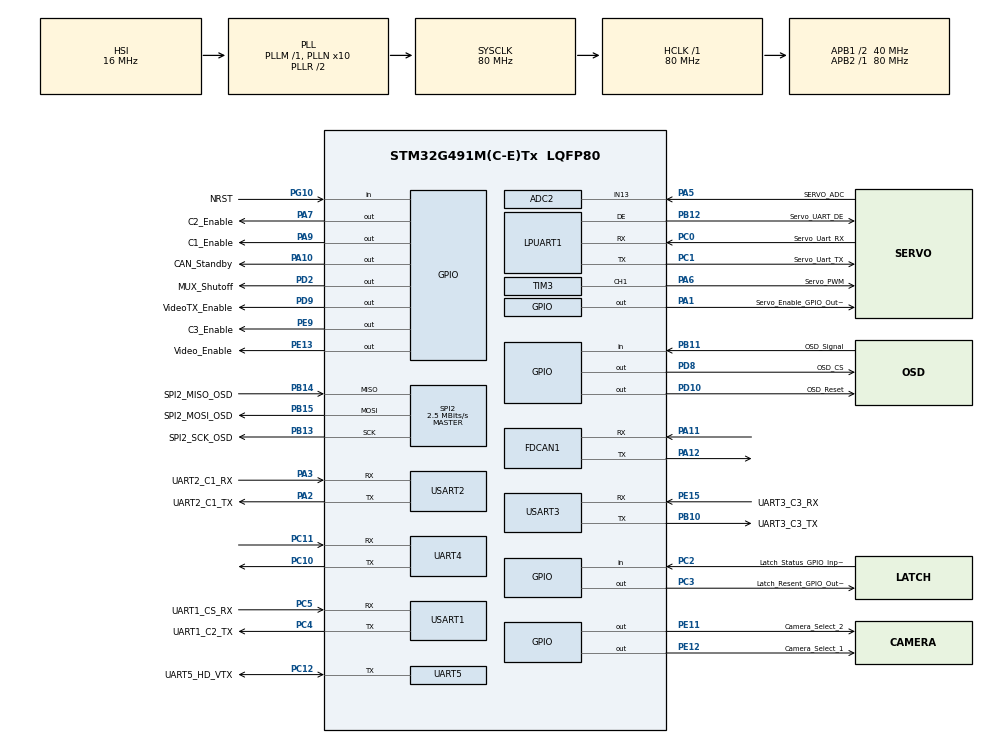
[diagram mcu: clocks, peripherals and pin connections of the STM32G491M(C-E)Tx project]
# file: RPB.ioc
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ADC2.Channel-0\#ChannelRegularConversion=ADC_CHANNEL_13
ADC2.NbrOfConversionFlag=1
ADC2.OffsetNumber-0\#ChannelRegularConversion=ADC_OFFSET_NONE
ADC2.Rank-0\#ChannelRegularConversion=1
ADC2.SamplingTime-0\#ChannelRegularConversion=ADC_SAMPLETIME_2CYCLES_5
FDCAN1.AutoRetransmission=ENABLE
FDCAN1.CalculateBaudRateNominal=1000000
FDCAN1.CalculateTimeBitNominal=1000
FDCAN1.CalculateTimeQuantumNominal=25.0
FDCAN1.DataSyncJumpWidth=7
FDCAN1.DataTimeSeg1=8
FDCAN1.DataTimeSeg2=7
FDCAN1.FrameFormat=FDCAN_FRAME_FD_BRS
FDCAN1.NominalPrescaler=1
FDCAN1.NominalSyncJumpWidth=6
FDCAN1.NominalTimeSeg1=33
FDCAN1.NominalTimeSeg2=6
FREERTOS.Tasks01=defaultTask,0,128,StartDefaultTask,Default,NULL,Dynamic,NULL,NULL
FREERTOS.configTOTAL_HEAP_SIZE=64000
FREERTOS.configUSE_NEWLIB_REENTRANT=1
Mcu.Family=STM32G4
Mcu.Name=STM32G491M(C-E)Tx
Mcu.Package=LQFP80
NVIC.FDCAN1_IT0_IRQn=true\:5\:0\:false\:false\:true\:true\:true\:true\:true
NVIC.PriorityGroup=NVIC_PRIORITYGROUP_4
NVIC.TIM4_IRQn=true\:15\:0\:false\:false\:true\:false\:false\:true\:true
NVIC.TimeBase=TIM4_IRQn
NVIC.TimeBaseIP=TIM4
NVIC.UART4_IRQn=true\:5\:0\:false\:false\:true\:true\:true\:true\:true
PA1.GPIO_Label=Servo_Enable_GPIO_Output
PA1.Signal=GPIO_Output
PA10.GPIO_Label=CAN_Standby
PA10.Signal=GPIO_Output
PA11.Mode=FDCAN_Activate
PA11.Signal=FDCAN1_RX
PA12.Mode=FDCAN_Activate
PA12.Signal=FDCAN1_TX
PA13.Mode=Trace_Asynchronous_SW
PA13.Signal=SYS_JTMS-SWDIO
PA14.Mode=Trace_Asynchronous_SW
PA14.Signal=SYS_JTCK-SWCLK
PA2.GPIO_Label=UART2_C1_TX
PA2.Mode=Asynchronous
PA2.Signal=USART2_TX
PA3.GPIO_Label=UART2_C1_RX
PA3.Mode=Asynchronous
PA3.Signal=USART2_RX
PA5.GPIO_Label=SERVO_ADC
PA5.Mode=IN13-Single-Ended
PA5.Signal=ADC2_IN13
PA6.GPIO_Label=Servo_PWM
PA6.Signal=S_TIM3_CH1
PA7.GPIO_Label=C2_Enable
PA7.Signal=GPIO_Output
PA9.GPIO_Label=C1_Enable
PA9.Signal=GPIO_Output
PB10.GPIO_Label=UART3_C3_TX
PB10.Mode=Asynchronous
PB10.Signal=USART3_TX
PB11.GPIO_Label=OSD_Signal
PB11.Signal=GPIO_Input
PB12.GPIO_Label=Servo_UART_DE
PB12.Mode=Hardware Flow Control (RS485)
PB12.Signal=LPUART1_DE
PB13.GPIO_Label=SPI2_SCK_OSD
PB13.Mode=Full_Duplex_Master
PB13.Signal=SPI2_SCK
PB14.GPIO_Label=SPI2_MISO_OSD
PB14.Mode=Full_Duplex_Master
PB14.Signal=SPI2_MISO
PB15.GPIO_Label=SPI2_MOSI_OSD
PB15.Mode=Full_Duplex_Master
PB15.Signal=SPI2_MOSI
PB3.Mode=Trace_Asynchronous_SW
PB3.Signal=SYS_JTDO-SWO
PC0.GPIO_Label=Servo_Uart_RX
PC0.Mode=Asynchronous
PC0.Signal=LPUART1_RX
PC1.GPIO_Label=Servo_Uart_TX
PC1.Mode=Asynchronous
PC1.Signal=LPUART1_TX
PC10.Mode=Asynchronous
PC10.Signal=UART4_TX
PC11.Mode=Asynchronous
PC11.Signal=UART4_RX
PC12.GPIO_Label=UART5_HD_VTX
PC12.Mode=Half_duplex(single_wire_mode)
PC12.Signal=UART5_TX
PC2.GPIO_Label=Latch_Status_GPIO_Input
PC2.Signal=GPIO_Input
PC3.GPIO_Label=Latch_Resent_GPIO_Output
PC3.Signal=GPIO_Output
PC4.GPIO_Label=UART1_C2_TX
PC4.Mode=Asynchronous
PC4.Signal=USART1_TX
PC5.GPIO_Label=UART1_CS_RX
PC5.Mode=Asynchronous
PC5.Signal=USART1_RX
PD10.GPIO_Label=OSD_Reset
PD10.Signal=GPIO_Output
PD2.GPIO_Label=MUX_Shutoff
PD2.Signal=GPIO_Output
PD8.GPIO_Label=OSD_CS
PD8.Signal=GPIO_Output
PD9.GPIO_Label=VideoTX_Enable
PD9.Signal=GPIO_Output
PE11.GPIO_Label=Camera_Select_2
PE11.Signal=GPIO_Output
PE12.GPIO_Label=Camera_Select_1
PE12.Signal=GPIO_Output
PE13.GPIO_Label=Video_Enable
PE13.Signal=GPIO_Output
PE15.GPIO_Label=UART3_C3_RX
PE15.Mode=Asynchronous
PE15.Signal=USART3_RX
PE9.GPIO_Label=C3_Enable
PE9.Signal=GPIO_Output
PG10-NRST.GPIO_Label=NRST
PG10-NRST.Signal=GPIO_Input
ProjectManager.HeapSize=0x200
ProjectManager.StackSize=0x400
ProjectManager.TargetToolchain=STM32CubeIDE
RCC.ADC12Freq_Value=80000000
RCC.ADC345Freq_Value=80000000
RCC.AHBFreq_Value=80000000
RCC.APB1CLKDivider=RCC_HCLK_DIV2
RCC.APB1Freq_Value=40000000
RCC.APB1TimFreq_Value=80000000
RCC.APB2Freq_Value=80000000
RCC.APB2TimFreq_Value=80000000
RCC.CortexFreq_Value=80000000
RCC.EXTERNAL_CLOCK_VALUE=12288000
RCC.HCLKFreq_Value=80000000
RCC.HSE_VALUE=8000000
RCC.HSI48_VALUE=48000000
RCC.HSI_VALUE=16000000
RCC.LSE_VALUE=32768
RCC.PLLN=10
RCC.SYSCLKFreq_VALUE=80000000
RCC.SYSCLKSource=RCC_SYSCLKSOURCE_PLLCLK
RCC.VCOOutputFreq_Value=160000000
SH.S_TIM3_CH1.0=TIM3_CH1,PWM Generation1 CH1
SPI2.BaudRatePrescaler=SPI_BAUDRATEPRESCALER_16
SPI2.CalculateBaudRate=2.5 MBits/s
SPI2.DataSize=SPI_DATASIZE_8BIT
SPI2.Direction=SPI_DIRECTION_2LINES
SPI2.Mode=SPI_MODE_MASTER
SPI2.VirtualType=VM_MASTER
TIM3.Channel-PWM\ Generation1\ CH1=TIM_CHANNEL_1
TIM3.Prescaler=16
UART5.BaudRate=9600
USART1.VirtualMode-Asynchronous=VM_ASYNC
USART2.VirtualMode-Asynchronous=VM_ASYNC
USART3.VirtualMode-Asynchronous=VM_ASYNC
VP_CRC_VS_CRC.Mode=CRC_Activate
VP_FREERTOS_VS_CMSIS_V1.Mode=CMSIS_V1
VP_SYS_VS_DBSignals.Mode=DisableDeadBatterySignals
VP_SYS_VS_tim4.Mode=TIM4
board=custom

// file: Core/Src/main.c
/* USER CODE BEGIN Header */
/**
  ******************************************************************************
  * @file           : main.c
  * @brief          : Main program body
  ******************************************************************************
  * @attention
  *
  * Copyright (c) 2025 STMicroelectronics.
  * All rights reserved.
  *
  * This software is licensed under terms that can be found in the LICENSE file
  * in the root directory of this software component.
  * If no LICENSE file comes with this software, it is provided AS-IS.
  *
  ******************************************************************************
  */
/* USER CODE END Header */
#include "main.h"
#include "cmsis_os.h"

/* USER CODE BEGIN Includes */
#include "RunInterface.hpp"
/* USER CODE END Includes */

ADC_HandleTypeDef hadc2;

CRC_HandleTypeDef hcrc;

FDCAN_HandleTypeDef hfdcan1;

UART_HandleTypeDef hlpuart1;

SPI_HandleTypeDef hspi2;

TIM_HandleTypeDef htim3;

osThreadId defaultTaskHandle;

void SystemClock_Config(void);
static void MX_GPIO_Init(void);
static void MX_FDCAN1_Init(void);
static void MX_UART4_Init(void);
static void MX_UART5_Init(void);
static void MX_USART1_UART_Init(void);
static void MX_USART2_UART_Init(void);
static void MX_USART3_UART_Init(void);
static void MX_LPUART1_UART_Init(void);
static void MX_ADC2_Init(void);
static void MX_SPI2_Init(void);
static void MX_TIM3_Init(void);
static void MX_CRC_Init(void);
void StartDefaultTask(void const * argument);

int main(void)
{

  /* MCU Configuration--------------------------------------------------------*/

  /* Reset of all peripherals, Initializes the Flash interface and the Systick. */
  HAL_Init();

  /* Configure the system clock */
  SystemClock_Config();

  /* Initialize all configured peripherals */
  MX_GPIO_Init();
  MX_FDCAN1_Init();
  MX_UART4_Init();
  MX_UART5_Init();
  MX_USART1_UART_Init();
  MX_USART2_UART_Init();
  MX_USART3_UART_Init();
  MX_LPUART1_UART_Init();
  MX_ADC2_Init();
  MX_SPI2_Init();
  MX_TIM3_Init();
  MX_CRC_Init();
  /* USER CODE BEGIN 2 */
  run_interface();
  /* USER CODE END 2 */

  /* Create the thread(s) */
  /* definition and creation of defaultTask */
  osThreadDef(defaultTask, StartDefaultTask, osPriorityNormal, 0, 128);
  defaultTaskHandle = osThreadCreate(osThread(defaultTask), NULL);

  /* Start scheduler */
  osKernelStart();

  /* We should never get here as control is now taken by the scheduler */

  /* Infinite loop */
  while (1)
  {

  }
}

void SystemClock_Config(void)
{
  RCC_OscInitTypeDef RCC_OscInitStruct = {0};
  RCC_ClkInitTypeDef RCC_ClkInitStruct = {0};

  /** Configure the main internal regulator output voltage
  */
  HAL_PWREx_ControlVoltageScaling(PWR_REGULATOR_VOLTAGE_SCALE1);

  /** Initializes the RCC Oscillators according to the specified parameters
  * in the RCC_OscInitTypeDef structure.
  */
  RCC_OscInitStruct.OscillatorType = RCC_OSCILLATORTYPE_HSI;
  RCC_OscInitStruct.HSIState = RCC_HSI_ON;
  RCC_OscInitStruct.HSICalibrationValue = RCC_HSICALIBRATION_DEFAULT;
  RCC_OscInitStruct.PLL.PLLState = RCC_PLL_ON;
  RCC_OscInitStruct.PLL.PLLSource = RCC_PLLSOURCE_HSI;
  RCC_OscInitStruct.PLL.PLLM = RCC_PLLM_DIV1;
  RCC_OscInitStruct.PLL.PLLN = 10;
  RCC_OscInitStruct.PLL.PLLP = RCC_PLLP_DIV2;
  RCC_OscInitStruct.PLL.PLLQ = RCC_PLLQ_DIV2;
  RCC_OscInitStruct.PLL.PLLR = RCC_PLLR_DIV2;
  if (HAL_RCC_OscConfig(&RCC_OscInitStruct) != HAL_OK)
  {
    Error_Handler();
  }

  /** Initializes the CPU, AHB and APB buses clocks
  */
  RCC_ClkInitStruct.ClockType = RCC_CLOCKTYPE_HCLK|RCC_CLOCKTYPE_SYSCLK
                              |RCC_CLOCKTYPE_PCLK1|RCC_CLOCKTYPE_PCLK2;
  RCC_ClkInitStruct.SYSCLKSource = RCC_SYSCLKSOURCE_PLLCLK;
  RCC_ClkInitStruct.AHBCLKDivider = RCC_SYSCLK_DIV1;
  RCC_ClkInitStruct.APB1CLKDivider = RCC_HCLK_DIV2;
  RCC_ClkInitStruct.APB2CLKDivider = RCC_HCLK_DIV1;

  if (HAL_RCC_ClockConfig(&RCC_ClkInitStruct, FLASH_LATENCY_2) != HAL_OK)
  {
    Error_Handler();
  }
}

static void MX_ADC2_Init(void)
{

  ADC_ChannelConfTypeDef sConfig = {0};

  /** Common config
  */
  hadc2.Instance = ADC2;
  hadc2.Init.ClockPrescaler = ADC_CLOCK_SYNC_PCLK_DIV2;
  hadc2.Init.Resolution = ADC_RESOLUTION_12B;
  hadc2.Init.DataAlign = ADC_DATAALIGN_RIGHT;
  hadc2.Init.GainCompensation = 0;
  hadc2.Init.ScanConvMode = ADC_SCAN_DISABLE;
  hadc2.Init.EOCSelection = ADC_EOC_SINGLE_CONV;
  hadc2.Init.LowPowerAutoWait = DISABLE;
  hadc2.Init.ContinuousConvMode = DISABLE;
  hadc2.Init.NbrOfConversion = 1;
  hadc2.Init.DiscontinuousConvMode = DISABLE;
  hadc2.Init.ExternalTrigConv = ADC_SOFTWARE_START;
  hadc2.Init.ExternalTrigConvEdge = ADC_EXTERNALTRIGCONVEDGE_NONE;
  hadc2.Init.DMAContinuousRequests = DISABLE;
  hadc2.Init.Overrun = ADC_OVR_DATA_PRESERVED;
  hadc2.Init.OversamplingMode = DISABLE;
  if (HAL_ADC_Init(&hadc2) != HAL_OK)
  {
    Error_Handler();
  }

  /** Configure Regular Channel
  */
  sConfig.Channel = ADC_CHANNEL_13;
  sConfig.Rank = ADC_REGULAR_RANK_1;
  sConfig.SamplingTime = ADC_SAMPLETIME_2CYCLES_5;
  sConfig.SingleDiff = ADC_SINGLE_ENDED;
  sConfig.OffsetNumber = ADC_OFFSET_NONE;
  sConfig.Offset = 0;
  if (HAL_ADC_ConfigChannel(&hadc2, &sConfig) != HAL_OK)
  {
    Error_Handler();
  }

}

static void MX_CRC_Init(void)
{

  hcrc.Instance = CRC;
  hcrc.Init.DefaultPolynomialUse = DEFAULT_POLYNOMIAL_ENABLE;
  hcrc.Init.DefaultInitValueUse = DEFAULT_INIT_VALUE_ENABLE;
  hcrc.Init.InputDataInversionMode = CRC_INPUTDATA_INVERSION_NONE;
  hcrc.Init.OutputDataInversionMode = CRC_OUTPUTDATA_INVERSION_DISABLE;
  hcrc.InputDataFormat = CRC_INPUTDATA_FORMAT_BYTES;
  if (HAL_CRC_Init(&hcrc) != HAL_OK)
  {
    Error_Handler();
  }

}

static void MX_FDCAN1_Init(void)
{

  hfdcan1.Instance = FDCAN1;
  hfdcan1.Init.ClockDivider = FDCAN_CLOCK_DIV1;
  hfdcan1.Init.FrameFormat = FDCAN_FRAME_FD_BRS;
  hfdcan1.Init.Mode = FDCAN_MODE_NORMAL;
  hfdcan1.Init.AutoRetransmission = ENABLE;
  hfdcan1.Init.TransmitPause = DISABLE;
  hfdcan1.Init.ProtocolException = DISABLE;
  hfdcan1.Init.NominalPrescaler = 1;
  hfdcan1.Init.NominalSyncJumpWidth = 6;
  hfdcan1.Init.NominalTimeSeg1 = 33;
  hfdcan1.Init.NominalTimeSeg2 = 6;
  hfdcan1.Init.DataPrescaler = 1;
  hfdcan1.Init.DataSyncJumpWidth = 7;
  hfdcan1.Init.DataTimeSeg1 = 8;
  hfdcan1.Init.DataTimeSeg2 = 7;
  hfdcan1.Init.StdFiltersNbr = 0;
  hfdcan1.Init.ExtFiltersNbr = 0;
  hfdcan1.Init.TxFifoQueueMode = FDCAN_TX_FIFO_OPERATION;
  if (HAL_FDCAN_Init(&hfdcan1) != HAL_OK)
  {
    Error_Handler();
  }

}

static void MX_LPUART1_UART_Init(void)
{

  hlpuart1.Instance = LPUART1;
  hlpuart1.Init.BaudRate = 209700;
  hlpuart1.Init.WordLength = UART_WORDLENGTH_8B;
  hlpuart1.Init.StopBits = UART_STOPBITS_1;
  hlpuart1.Init.Parity = UART_PARITY_NONE;
  hlpuart1.Init.Mode = UART_MODE_TX_RX;
  hlpuart1.Init.HwFlowCtl = UART_HWCONTROL_NONE;
  hlpuart1.Init.OneBitSampling = UART_ONE_BIT_SAMPLE_DISABLE;
  hlpuart1.Init.ClockPrescaler = UART_PRESCALER_DIV1;
  hlpuart1.AdvancedInit.AdvFeatureInit = UART_ADVFEATURE_NO_INIT;
  if (HAL_UART_Init(&hlpuart1) != HAL_OK)
  {
    Error_Handler();
  }
  if (HAL_UARTEx_SetTxFifoThreshold(&hlpuart1, UART_TXFIFO_THRESHOLD_1_8) != HAL_OK)
  {
    Error_Handler();
  }
  if (HAL_UARTEx_SetRxFifoThreshold(&hlpuart1, UART_RXFIFO_THRESHOLD_1_8) != HAL_OK)
  {
    Error_Handler();
  }
  if (HAL_UARTEx_DisableFifoMode(&hlpuart1) != HAL_OK)
  {
    Error_Handler();
  }
  if (HAL_RS485Ex_Init(&hlpuart1, UART_DE_POLARITY_HIGH, 0, 0) != HAL_OK)
  {
    Error_Handler();
  }

}

static void MX_UART4_Init(void)
{

  LL_USART_InitTypeDef USART_InitStruct = {0};

  LL_GPIO_InitTypeDef GPIO_InitStruct = {0};
  RCC_PeriphCLKInitTypeDef PeriphClkInit = {0};

  /** Initializes the peripherals clocks
  */
  PeriphClkInit.PeriphClockSelection = RCC_PERIPHCLK_UART4;
  PeriphClkInit.Uart4ClockSelection = RCC_UART4CLKSOURCE_PCLK1;
  if (HAL_RCCEx_PeriphCLKConfig(&PeriphClkInit) != HAL_OK)
  {
    Error_Handler();
  }

  /* Peripheral clock enable */
  LL_APB1_GRP1_EnableClock(LL_APB1_GRP1_PERIPH_UART4);

  LL_AHB2_GRP1_EnableClock(LL_AHB2_GRP1_PERIPH_GPIOC);
  /**UART4 GPIO Configuration
  PC10   ------> UART4_TX
  PC11   ------> UART4_RX
  */
  GPIO_InitStruct.Pin = LL_GPIO_PIN_10;
  GPIO_InitStruct.Mode = LL_GPIO_MODE_ALTERNATE;
  GPIO_InitStruct.Speed = LL_GPIO_SPEED_FREQ_LOW;
  GPIO_InitStruct.OutputType = LL_GPIO_OUTPUT_PUSHPULL;
  GPIO_InitStruct.Pull = LL_GPIO_PULL_NO;
  GPIO_InitStruct.Alternate = LL_GPIO_AF_5;
  LL_GPIO_Init(GPIOC, &GPIO_InitStruct);

  GPIO_InitStruct.Pin = LL_GPIO_PIN_11;
  GPIO_InitStruct.Mode = LL_GPIO_MODE_ALTERNATE;
  GPIO_InitStruct.Speed = LL_GPIO_SPEED_FREQ_LOW;
  GPIO_InitStruct.OutputType = LL_GPIO_OUTPUT_PUSHPULL;
  GPIO_InitStruct.Pull = LL_GPIO_PULL_NO;
  GPIO_InitStruct.Alternate = LL_GPIO_AF_5;
  LL_GPIO_Init(GPIOC, &GPIO_InitStruct);

  /* UART4 interrupt Init */
  NVIC_SetPriority(UART4_IRQn, NVIC_EncodePriority(NVIC_GetPriorityGrouping(),5, 0));
  NVIC_EnableIRQ(UART4_IRQn);

  USART_InitStruct.PrescalerValue = LL_USART_PRESCALER_DIV1;
  USART_InitStruct.BaudRate = 115200;
  USART_InitStruct.DataWidth = LL_USART_DATAWIDTH_8B;
  USART_InitStruct.StopBits = LL_USART_STOPBITS_1;
  USART_InitStruct.Parity = LL_USART_PARITY_NONE;
  USART_InitStruct.TransferDirection = LL_USART_DIRECTION_TX_RX;
  USART_InitStruct.HardwareFlowControl = LL_USART_HWCONTROL_NONE;
  USART_InitStruct.OverSampling = LL_USART_OVERSAMPLING_16;
  LL_USART_Init(UART4, &USART_InitStruct);
  LL_USART_DisableFIFO(UART4);
  LL_USART_SetTXFIFOThreshold(UART4, LL_USART_FIFOTHRESHOLD_1_8);
  LL_USART_SetRXFIFOThreshold(UART4, LL_USART_FIFOTHRESHOLD_1_8);
  LL_USART_ConfigAsyncMode(UART4);

  LL_USART_Enable(UART4);

  /* Polling UART4 initialisation */
  while((!(LL_USART_IsActiveFlag_TEACK(UART4))) || (!(LL_USART_IsActiveFlag_REACK(UART4))))
  {
  }

}

static void MX_UART5_Init(void)
{

  LL_USART_InitTypeDef USART_InitStruct = {0};

  LL_GPIO_InitTypeDef GPIO_InitStruct = {0};
  RCC_PeriphCLKInitTypeDef PeriphClkInit = {0};

  /** Initializes the peripherals clocks
  */
  PeriphClkInit.PeriphClockSelection = RCC_PERIPHCLK_UART5;
  PeriphClkInit.Uart5ClockSelection = RCC_UART5CLKSOURCE_PCLK1;
  if (HAL_RCCEx_PeriphCLKConfig(&PeriphClkInit) != HAL_OK)
  {
    Error_Handler();
  }

  /* Peripheral clock enable */
  LL_APB1_GRP1_EnableClock(LL_APB1_GRP1_PERIPH_UART5);

  LL_AHB2_GRP1_EnableClock(LL_AHB2_GRP1_PERIPH_GPIOC);
  /**UART5 GPIO Configuration
  PC12   ------> UART5_TX
  */
  GPIO_InitStruct.Pin = LL_GPIO_PIN_12;
  GPIO_InitStruct.Mode = LL_GPIO_MODE_ALTERNATE;
  GPIO_InitStruct.Speed = LL_GPIO_SPEED_FREQ_LOW;
  GPIO_InitStruct.OutputType = LL_GPIO_OUTPUT_OPENDRAIN;
  GPIO_InitStruct.Pull = LL_GPIO_PULL_NO;
  GPIO_InitStruct.Alternate = LL_GPIO_AF_5;
  LL_GPIO_Init(GPIOC, &GPIO_InitStruct);

  USART_InitStruct.PrescalerValue = LL_USART_PRESCALER_DIV1;
  USART_InitStruct.BaudRate = 9600;
  USART_InitStruct.DataWidth = LL_USART_DATAWIDTH_8B;
  USART_InitStruct.StopBits = LL_USART_STOPBITS_1;
  USART_InitStruct.Parity = LL_USART_PARITY_NONE;
  USART_InitStruct.TransferDirection = LL_USART_DIRECTION_TX_RX;
  USART_InitStruct.OverSampling = LL_USART_OVERSAMPLING_16;
  LL_USART_Init(UART5, &USART_InitStruct);
  LL_USART_DisableFIFO(UART5);
  LL_USART_SetTXFIFOThreshold(UART5, LL_USART_FIFOTHRESHOLD_1_8);
  LL_USART_SetRXFIFOThreshold(UART5, LL_USART_FIFOTHRESHOLD_1_8);
  LL_USART_ConfigHalfDuplexMode(UART5);

  LL_USART_Enable(UART5);

  /* Polling UART5 initialisation */
  while((!(LL_USART_IsActiveFlag_TEACK(UART5))) || (!(LL_USART_IsActiveFlag_REACK(UART5))))
  {
  }

}

static void MX_USART1_UART_Init(void)
{

  LL_USART_InitTypeDef USART_InitStruct = {0};

  LL_GPIO_InitTypeDef GPIO_InitStruct = {0};
  RCC_PeriphCLKInitTypeDef PeriphClkInit = {0};

  /** Initializes the peripherals clocks
  */
  PeriphClkInit.PeriphClockSelection = RCC_PERIPHCLK_USART1;
  PeriphClkInit.Usart1ClockSelection = RCC_USART1CLKSOURCE_PCLK2;
  if (HAL_RCCEx_PeriphCLKConfig(&PeriphClkInit) != HAL_OK)
  {
    Error_Handler();
  }

  /* Peripheral clock enable */
  LL_APB2_GRP1_EnableClock(LL_APB2_GRP1_PERIPH_USART1);

  LL_AHB2_GRP1_EnableClock(LL_AHB2_GRP1_PERIPH_GPIOC);
  /**USART1 GPIO Configuration
  PC4   ------> USART1_TX
  PC5   ------> USART1_RX
  */
  GPIO_InitStruct.Pin = LL_GPIO_PIN_4;
  GPIO_InitStruct.Mode = LL_GPIO_MODE_ALTERNATE;
  GPIO_InitStruct.Speed = LL_GPIO_SPEED_FREQ_LOW;
  GPIO_InitStruct.OutputType = LL_GPIO_OUTPUT_PUSHPULL;
  GPIO_InitStruct.Pull = LL_GPIO_PULL_NO;
  GPIO_InitStruct.Alternate = LL_GPIO_AF_7;
  LL_GPIO_Init(GPIOC, &GPIO_InitStruct);

  GPIO_InitStruct.Pin = LL_GPIO_PIN_5;
  GPIO_InitStruct.Mode = LL_GPIO_MODE_ALTERNATE;
  GPIO_InitStruct.Speed = LL_GPIO_SPEED_FREQ_LOW;
  GPIO_InitStruct.OutputType = LL_GPIO_OUTPUT_PUSHPULL;
  GPIO_InitStruct.Pull = LL_GPIO_PULL_NO;
  GPIO_InitStruct.Alternate = LL_GPIO_AF_7;
  LL_GPIO_Init(GPIOC, &GPIO_InitStruct);

  USART_InitStruct.PrescalerValue = LL_USART_PRESCALER_DIV1;
  USART_InitStruct.BaudRate = 115200;
  USART_InitStruct.DataWidth = LL_USART_DATAWIDTH_8B;
  USART_InitStruct.StopBits = LL_USART_STOPBITS_1;
  USART_InitStruct.Parity = LL_USART_PARITY_NONE;
  USART_InitStruct.TransferDirection = LL_USART_DIRECTION_TX_RX;
  USART_InitStruct.HardwareFlowControl = LL_USART_HWCONTROL_NONE;
  USART_InitStruct.OverSampling = LL_USART_OVERSAMPLING_16;
  LL_USART_Init(USART1, &USART_InitStruct);
  LL_USART_SetTXFIFOThreshold(USART1, LL_USART_FIFOTHRESHOLD_1_8);
  LL_USART_SetRXFIFOThreshold(USART1, LL_USART_FIFOTHRESHOLD_1_8);
  LL_USART_DisableFIFO(USART1);
  LL_USART_ConfigAsyncMode(USART1);

  LL_USART_Enable(USART1);

  /* Polling USART1 initialisation */
  while((!(LL_USART_IsActiveFlag_TEACK(USART1))) || (!(LL_USART_IsActiveFlag_REACK(USART1))))
  {
  }

}

static void MX_USART2_UART_Init(void)
{

  LL_USART_InitTypeDef USART_InitStruct = {0};

  LL_GPIO_InitTypeDef GPIO_InitStruct = {0};
  RCC_PeriphCLKInitTypeDef PeriphClkInit = {0};

  /** Initializes the peripherals clocks
  */
  PeriphClkInit.PeriphClockSelection = RCC_PERIPHCLK_USART2;
  PeriphClkInit.Usart2ClockSelection = RCC_USART2CLKSOURCE_PCLK1;
  if (HAL_RCCEx_PeriphCLKConfig(&PeriphClkInit) != HAL_OK)
  {
    Error_Handler();
  }

  /* Peripheral clock enable */
  LL_APB1_GRP1_EnableClock(LL_APB1_GRP1_PERIPH_USART2);

  LL_AHB2_GRP1_EnableClock(LL_AHB2_GRP1_PERIPH_GPIOA);
  /**USART2 GPIO Configuration
  PA2   ------> USART2_TX
  PA3   ------> USART2_RX
  */
  GPIO_InitStruct.Pin = LL_GPIO_PIN_2;
  GPIO_InitStruct.Mode = LL_GPIO_MODE_ALTERNATE;
  GPIO_InitStruct.Speed = LL_GPIO_SPEED_FREQ_LOW;
  GPIO_InitStruct.OutputType = LL_GPIO_OUTPUT_PUSHPULL;
  GPIO_InitStruct.Pull = LL_GPIO_PULL_NO;
  GPIO_InitStruct.Alternate = LL_GPIO_AF_7;
  LL_GPIO_Init(GPIOA, &GPIO_InitStruct);

  GPIO_InitStruct.Pin = LL_GPIO_PIN_3;
  GPIO_InitStruct.Mode = LL_GPIO_MODE_ALTERNATE;
  GPIO_InitStruct.Speed = LL_GPIO_SPEED_FREQ_LOW;
  GPIO_InitStruct.OutputType = LL_GPIO_OUTPUT_PUSHPULL;
  GPIO_InitStruct.Pull = LL_GPIO_PULL_NO;
  GPIO_InitStruct.Alternate = LL_GPIO_AF_7;
  LL_GPIO_Init(GPIOA, &GPIO_InitStruct);

  USART_InitStruct.PrescalerValue = LL_USART_PRESCALER_DIV1;
  USART_InitStruct.BaudRate = 115200;
  USART_InitStruct.DataWidth = LL_USART_DATAWIDTH_8B;
  USART_InitStruct.StopBits = LL_USART_STOPBITS_1;
  USART_InitStruct.Parity = LL_USART_PARITY_NONE;
  USART_InitStruct.TransferDirection = LL_USART_DIRECTION_TX_RX;
  USART_InitStruct.HardwareFlowControl = LL_USART_HWCONTROL_NONE;
  USART_InitStruct.OverSampling = LL_USART_OVERSAMPLING_16;
  LL_USART_Init(USART2, &USART_InitStruct);
  LL_USART_SetTXFIFOThreshold(USART2, LL_USART_FIFOTHRESHOLD_1_8);
  LL_USART_SetRXFIFOThreshold(USART2, LL_USART_FIFOTHRESHOLD_1_8);
  LL_USART_DisableFIFO(USART2);
  LL_USART_ConfigAsyncMode(USART2);

  LL_USART_Enable(USART2);

  /* Polling USART2 initialisation */
  while((!(LL_USART_IsActiveFlag_TEACK(USART2))) || (!(LL_USART_IsActiveFlag_REACK(USART2))))
  {
  }

}

static void MX_USART3_UART_Init(void)
{

  LL_USART_InitTypeDef USART_InitStruct = {0};

  LL_GPIO_InitTypeDef GPIO_InitStruct = {0};
  RCC_PeriphCLKInitTypeDef PeriphClkInit = {0};

  /** Initializes the peripherals clocks
  */
  PeriphClkInit.PeriphClockSelection = RCC_PERIPHCLK_USART3;
  PeriphClkInit.Usart3ClockSelection = RCC_USART3CLKSOURCE_PCLK1;
  if (HAL_RCCEx_PeriphCLKConfig(&PeriphClkInit) != HAL_OK)
  {
    Error_Handler();
  }

  /* Peripheral clock enable */
  LL_APB1_GRP1_EnableClock(LL_APB1_GRP1_PERIPH_USART3);

  LL_AHB2_GRP1_EnableClock(LL_AHB2_GRP1_PERIPH_GPIOE);
  LL_AHB2_GRP1_EnableClock(LL_AHB2_GRP1_PERIPH_GPIOB);
  /**USART3 GPIO Configuration
  PE15   ------> USART3_RX
  PB10   ------> USART3_TX
  */
  GPIO_InitStruct.Pin = LL_GPIO_PIN_15;
  GPIO_InitStruct.Mode = LL_GPIO_MODE_ALTERNATE;
  GPIO_InitStruct.Speed = LL_GPIO_SPEED_FREQ_LOW;
  GPIO_InitStruct.OutputType = LL_GPIO_OUTPUT_PUSHPULL;
  GPIO_InitStruct.Pull = LL_GPIO_PULL_NO;
  GPIO_InitStruct.Alternate = LL_GPIO_AF_7;
  LL_GPIO_Init(GPIOE, &GPIO_InitStruct);

  GPIO_InitStruct.Pin = LL_GPIO_PIN_10;
  GPIO_InitStruct.Mode = LL_GPIO_MODE_ALTERNATE;
  GPIO_InitStruct.Speed = LL_GPIO_SPEED_FREQ_LOW;
  GPIO_InitStruct.OutputType = LL_GPIO_OUTPUT_PUSHPULL;
  GPIO_InitStruct.Pull = LL_GPIO_PULL_NO;
  GPIO_InitStruct.Alternate = LL_GPIO_AF_7;
  LL_GPIO_Init(GPIOB, &GPIO_InitStruct);

  USART_InitStruct.PrescalerValue = LL_USART_PRESCALER_DIV1;
  USART_InitStruct.BaudRate = 115200;
  USART_InitStruct.DataWidth = LL_USART_DATAWIDTH_8B;
  USART_InitStruct.StopBits = LL_USART_STOPBITS_1;
  USART_InitStruct.Parity = LL_USART_PARITY_NONE;
  USART_InitStruct.TransferDirection = LL_USART_DIRECTION_TX_RX;
  USART_InitStruct.HardwareFlowControl = LL_USART_HWCONTROL_NONE;
  USART_InitStruct.OverSampling = LL_USART_OVERSAMPLING_16;
  LL_USART_Init(USART3, &USART_InitStruct);
  LL_USART_SetTXFIFOThreshold(USART3, LL_USART_FIFOTHRESHOLD_1_8);
  LL_USART_SetRXFIFOThreshold(USART3, LL_USART_FIFOTHRESHOLD_1_8);
  LL_USART_DisableFIFO(USART3);
  LL_USART_ConfigAsyncMode(USART3);

  LL_USART_Enable(USART3);

  /* Polling USART3 initialisation */
  while((!(LL_USART_IsActiveFlag_TEACK(USART3))) || (!(LL_USART_IsActiveFlag_REACK(USART3))))
  {
  }

}

static void MX_SPI2_Init(void)
{

  /* SPI2 parameter configuration*/
  hspi2.Instance = SPI2;
  hspi2.Init.Mode = SPI_MODE_MASTER;
  hspi2.Init.Direction = SPI_DIRECTION_2LINES;
  hspi2.Init.DataSize = SPI_DATASIZE_8BIT;
  hspi2.Init.CLKPolarity = SPI_POLARITY_LOW;
  hspi2.Init.CLKPhase = SPI_PHASE_1EDGE;
  hspi2.Init.NSS = SPI_NSS_SOFT;
  hspi2.Init.BaudRatePrescaler = SPI_BAUDRATEPRESCALER_16;
  hspi2.Init.FirstBit = SPI_FIRSTBIT_MSB;
  hspi2.Init.TIMode = SPI_TIMODE_DISABLE;
  hspi2.Init.CRCCalculation = SPI_CRCCALCULATION_DISABLE;
  hspi2.Init.CRCPolynomial = 7;
  hspi2.Init.CRCLength = SPI_CRC_LENGTH_DATASIZE;
  hspi2.Init.NSSPMode = SPI_NSS_PULSE_ENABLE;
  if (HAL_SPI_Init(&hspi2) != HAL_OK)
  {
    Error_Handler();
  }

}

static void MX_TIM3_Init(void)
{

  TIM_MasterConfigTypeDef sMasterConfig = {0};
  TIM_OC_InitTypeDef sConfigOC = {0};

  htim3.Instance = TIM3;
  htim3.Init.Prescaler = 16;
  htim3.Init.CounterMode = TIM_COUNTERMODE_UP;
  htim3.Init.Period = 65535;
  htim3.Init.ClockDivision = TIM_CLOCKDIVISION_DIV1;
  htim3.Init.AutoReloadPreload = TIM_AUTORELOAD_PRELOAD_DISABLE;
  if (HAL_TIM_PWM_Init(&htim3) != HAL_OK)
  {
    Error_Handler();
  }
  sMasterConfig.MasterOutputTrigger = TIM_TRGO_RESET;
  sMasterConfig.MasterSlaveMode = TIM_MASTERSLAVEMODE_DISABLE;
  if (HAL_TIMEx_MasterConfigSynchronization(&htim3, &sMasterConfig) != HAL_OK)
  {
    Error_Handler();
  }
  sConfigOC.OCMode = TIM_OCMODE_PWM1;
  sConfigOC.Pulse = 0;
  sConfigOC.OCPolarity = TIM_OCPOLARITY_HIGH;
  sConfigOC.OCFastMode = TIM_OCFAST_DISABLE;
  if (HAL_TIM_PWM_ConfigChannel(&htim3, &sConfigOC, TIM_CHANNEL_1) != HAL_OK)
  {
    Error_Handler();
  }
  HAL_TIM_MspPostInit(&htim3);

}

static void MX_GPIO_Init(void)
{
  GPIO_InitTypeDef GPIO_InitStruct = {0};

  /* GPIO Ports Clock Enable */
  __HAL_RCC_GPIOG_CLK_ENABLE();
  __HAL_RCC_GPIOC_CLK_ENABLE();
  __HAL_RCC_GPIOA_CLK_ENABLE();
  __HAL_RCC_GPIOE_CLK_ENABLE();
  __HAL_RCC_GPIOB_CLK_ENABLE();
  __HAL_RCC_GPIOD_CLK_ENABLE();

  /*Configure GPIO pin Output Level */
  HAL_GPIO_WritePin(Latch_Resent_GPIO_Output_GPIO_Port, Latch_Resent_GPIO_Output_Pin, GPIO_PIN_RESET);

  /*Configure GPIO pin Output Level */
  HAL_GPIO_WritePin(GPIOA, Servo_Enable_GPIO_Output_Pin|C2_Enable_Pin|C1_Enable_Pin|CAN_Standby_Pin, GPIO_PIN_RESET);

  /*Configure GPIO pin Output Level */
  HAL_GPIO_WritePin(GPIOE, C3_Enable_Pin|Camera_Select_2_Pin|Camera_Select_1_Pin|Video_Enable_Pin, GPIO_PIN_RESET);

  /*Configure GPIO pin Output Level */
  HAL_GPIO_WritePin(GPIOD, OSD_CS_Pin|VideoTX_Enable_Pin|OSD_Reset_Pin|MUX_Shutoff_Pin, GPIO_PIN_RESET);

  /*Configure GPIO pin : NRST_Pin */
  GPIO_InitStruct.Pin = NRST_Pin;
  GPIO_InitStruct.Mode = GPIO_MODE_INPUT;
  GPIO_InitStruct.Pull = GPIO_NOPULL;
  HAL_GPIO_Init(NRST_GPIO_Port, &GPIO_InitStruct);

  /*Configure GPIO pin : Latch_Status_GPIO_Input_Pin */
  GPIO_InitStruct.Pin = Latch_Status_GPIO_Input_Pin;
  GPIO_InitStruct.Mode = GPIO_MODE_INPUT;
  GPIO_InitStruct.Pull = GPIO_NOPULL;
  HAL_GPIO_Init(Latch_Status_GPIO_Input_GPIO_Port, &GPIO_InitStruct);

  /*Configure GPIO pin : Latch_Resent_GPIO_Output_Pin */
  GPIO_InitStruct.Pin = Latch_Resent_GPIO_Output_Pin;
  GPIO_InitStruct.Mode = GPIO_MODE_OUTPUT_PP;
  GPIO_InitStruct.Pull = GPIO_NOPULL;
  GPIO_InitStruct.Speed = GPIO_SPEED_FREQ_LOW;
  HAL_GPIO_Init(Latch_Resent_GPIO_Output_GPIO_Port, &GPIO_InitStruct);

  /*Configure GPIO pins : Servo_Enable_GPIO_Output_Pin C2_Enable_Pin C1_Enable_Pin CAN_Standby_Pin */
  GPIO_InitStruct.Pin = Servo_Enable_GPIO_Output_Pin|C2_Enable_Pin|C1_Enable_Pin|CAN_Standby_Pin;
  GPIO_InitStruct.Mode = GPIO_MODE_OUTPUT_PP;
  GPIO_InitStruct.Pull = GPIO_NOPULL;
  GPIO_InitStruct.Speed = GPIO_SPEED_FREQ_LOW;
  HAL_GPIO_Init(GPIOA, &GPIO_InitStruct);

  /*Configure GPIO pins : C3_Enable_Pin Camera_Select_2_Pin Camera_Select_1_Pin Video_Enable_Pin */
  GPIO_InitStruct.Pin = C3_Enable_Pin|Camera_Select_2_Pin|Camera_Select_1_Pin|Video_Enable_Pin;
  GPIO_InitStruct.Mode = GPIO_MODE_OUTPUT_PP;
  GPIO_InitStruct.Pull = GPIO_NOPULL;
  GPIO_InitStruct.Speed = GPIO_SPEED_FREQ_LOW;
  HAL_GPIO_Init(GPIOE, &GPIO_InitStruct);

  /*Configure GPIO pin : OSD_Signal_Pin */
  GPIO_InitStruct.Pin = OSD_Signal_Pin;
  GPIO_InitStruct.Mode = GPIO_MODE_INPUT;
  GPIO_InitStruct.Pull = GPIO_NOPULL;
  HAL_GPIO_Init(OSD_Signal_GPIO_Port, &GPIO_InitStruct);

  /*Configure GPIO pins : OSD_CS_Pin VideoTX_Enable_Pin OSD_Reset_Pin MUX_Shutoff_Pin */
  GPIO_InitStruct.Pin = OSD_CS_Pin|VideoTX_Enable_Pin|OSD_Reset_Pin|MUX_Shutoff_Pin;
  GPIO_InitStruct.Mode = GPIO_MODE_OUTPUT_PP;
  GPIO_InitStruct.Pull = GPIO_NOPULL;
  GPIO_InitStruct.Speed = GPIO_SPEED_FREQ_LOW;
  HAL_GPIO_Init(GPIOD, &GPIO_InitStruct);

}

void StartDefaultTask(void const * argument)
{
  for(;;)
  {
    osDelay(1);
  }
}

void HAL_TIM_PeriodElapsedCallback(TIM_HandleTypeDef *htim)
{
  if (htim->Instance == TIM4)
  {
    HAL_IncTick();
  }
}

void Error_Handler(void)
{
  __disable_irq();
  while (1)
  {
  }
}
